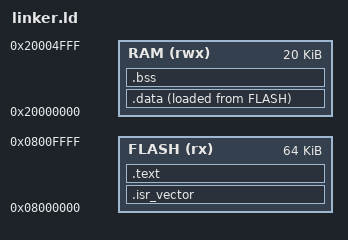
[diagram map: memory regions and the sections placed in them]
_estack = ORIGIN(RAM) + LENGTH(RAM);
MEMORY
{
    FLASH (rx) : ORIGIN = 0x08000000, LENGTH = 64K
    RAM (rwx)  : ORIGIN = 0x20000000, LENGTH = 20K
}

SECTIONS
{
    .isr_vector :
    {
        . = ALIGN(4);
        KEEP(*(.isr_vector))
        . = ALIGN(4);
    } >FLASH

    .text :
    {
        . = ALIGN(4);
        *(.text)
        *(.rodata)
        . = ALIGN(4);
    } >FLASH

    .data :
    {
        . = ALIGN(4);
        _sidata = .;
        _sdata = .;
        *(.data)
        _edata = .;
        . = ALIGN(4);
    } >RAM AT >FLASH

    .bss :
    {
        . = ALIGN(4);
        _sbss = .;
        *(.bss)
        _ebss = .;
        . = ALIGN(4);
    } >RAM
}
